# PY32Mxxx_DFP register map
Vendor: Puya; Series: PY32M; File version: 1.0.0
CPU: CM0+ r0p1, little endian, no MPU, no FPU, 4 interrupt priority bits
Registers are 32-bit, read-write, reset 0x0 unless marked. A register's access mark holds for its fields unless they carry their own. Offsets are from the block's base; [hi:lo] are bit positions; {n}, {i} and the like mark numbered series.

## CAN
Base 0x40006400
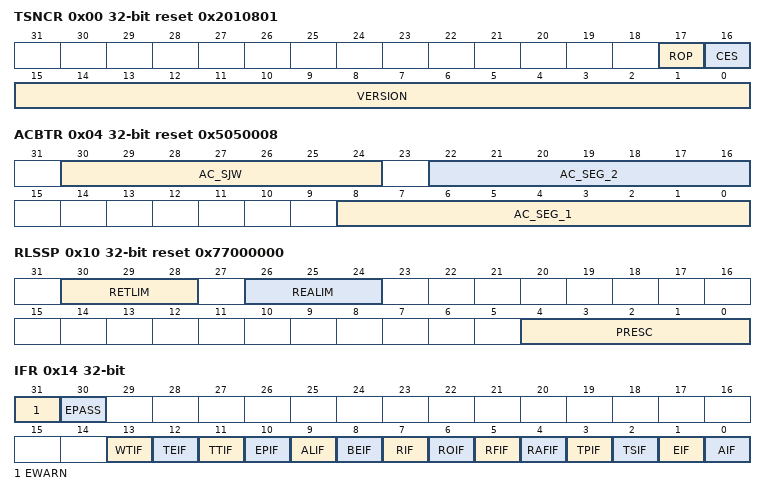
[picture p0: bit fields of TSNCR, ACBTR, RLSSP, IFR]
0x00 TSNCR reset 0x2010801
  [17] ROP, [16] CES, [15:0] VERSION ro
0x04 ACBTR reset 0x5050008
  [30:24] AC_SJW, [22:16] AC_SEG_2, [8:0] AC_SEG_1
0x10 RLSSP reset 0x77000000
  [30:28] RETLIM, [26:24] REALIM, [4:0] PRESC
0x14 IFR
  [31] EWARN ro, [30] EPASS ro, [13] WTIF, [12] TEIF, [11] TTIF, [10] EPIF, [9] ALIF, [8] BEIF, [7] RIF, [6] ROIF, [5] RFIF, [4] RAFIF, [3] TPIF, [2] TSIF, [1] EIF, [0] AIF
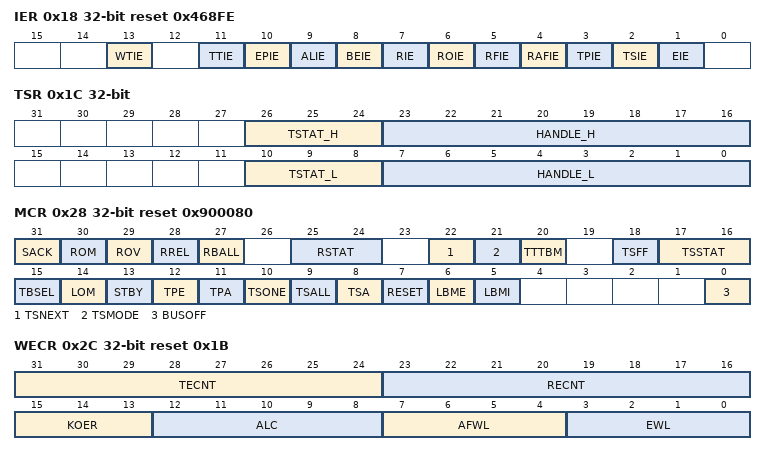
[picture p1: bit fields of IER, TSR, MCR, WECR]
0x18 IER reset 0x468FE
  [13] WTIE, [11] TTIE, [10] EPIE, [9] ALIE, [8] BEIE, [7] RIE, [6] ROIE, [5] RFIE, [4] RAFIE, [3] TPIE, [2] TSIE, [1] EIE
0x1C TSR ro
  [26:24] TSTAT_H, [23:16] HANDLE_H, [10:8] TSTAT_L, [7:0] HANDLE_L
0x28 MCR reset 0x900080
  [31] SACK, [30] ROM, [29] ROV ro, [28] RREL, [27] RBALL, [25:24] RSTAT ro, [22] TSNEXT, [21] TSMODE, [20] TTTBM, [18] TSFF ro, [17:16] TSSTAT ro, [15] TBSEL, [14] LOM, [13] STBY, [12] TPE, [11] TPA, [10] TSONE, [9] TSALL, [8] TSA, [7] RESET, [6] LBME, [5] LBMI, [0] BUSOFF
0x2C WECR reset 0x1B
  [31:24] TECNT ro, [23:16] RECNT ro, [15:13] KOER ro, [12:8] ALC ro, [7:4] AFWL, [3:0] EWL
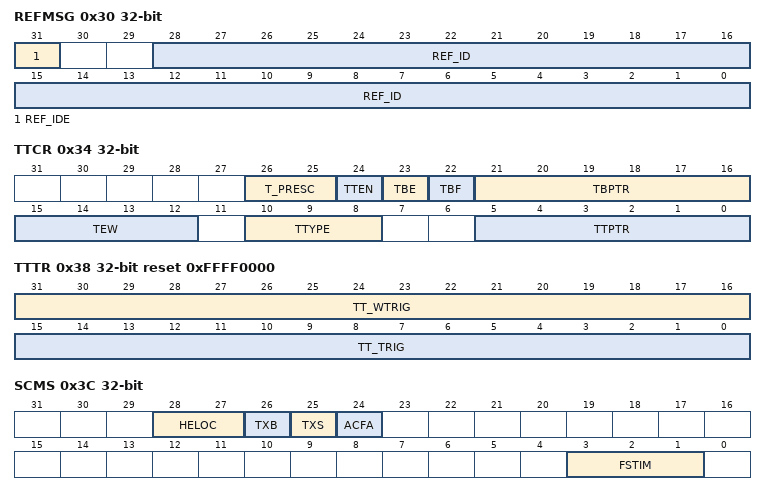
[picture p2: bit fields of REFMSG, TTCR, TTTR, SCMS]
0x30 REFMSG
  [31] REF_IDE, [28:0] REF_ID
0x34 TTCR
  [26:25] T_PRESC, [24] TTEN, [23] TBE, [22] TBF, [21:16] TBPTR, [15:12] TEW, [10:8] TTYPE, [5:0] TTPTR
0x38 TTTR reset 0xFFFF0000
  [31:16] TT_WTRIG, [15:0] TT_TRIG
0x3C SCMS
  [28:27] HELOC ro, [26] TXB ro, [25] TXS ro, [24] ACFA, [3:1] FSTIM
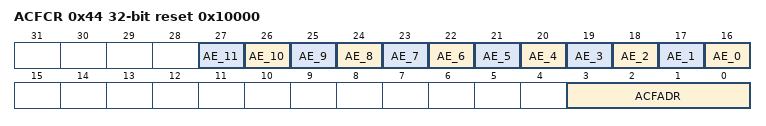
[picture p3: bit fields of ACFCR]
0x44 ACFCR reset 0x10000
  [n+16] AE_{n} (n=0..11), [3:0] ACFADR

## COMP1 — Comparator 1
Base 0x40010200
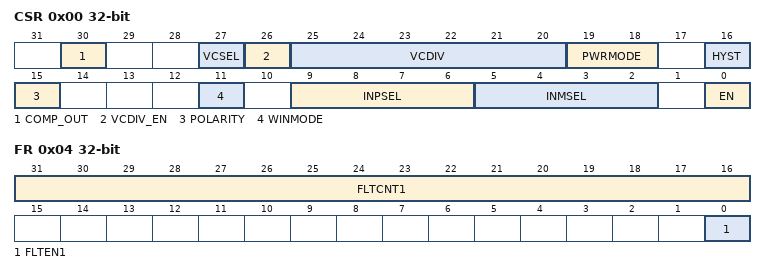
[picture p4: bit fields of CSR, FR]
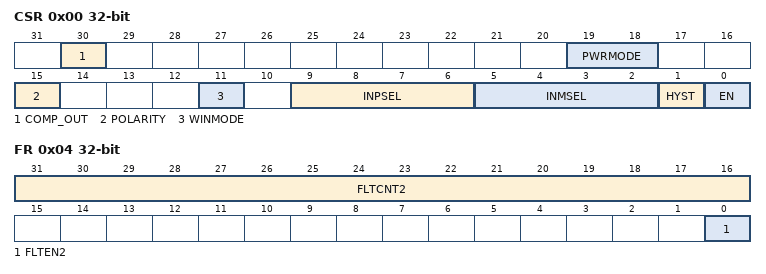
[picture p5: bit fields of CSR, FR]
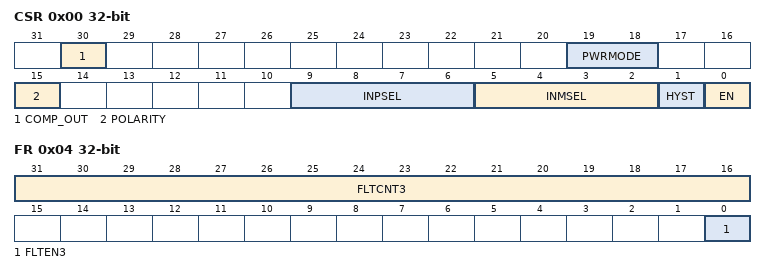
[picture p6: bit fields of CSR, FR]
0x00 CSR — COMP control and status register
  [30] COMP_OUT — Comparator output status
  [27] VCSEL
  [26] VCDIV_EN
  [25:20] VCDIV
  [19:18] PWRMODE — Comparator power mode selector
  [16] HYST — Comparator hysteresis enable selector
  [15] POLARITY — Comparator polarity selector
  [11] WINMODE — Comparator non-inverting input selector for window mode
  [9:6] INPSEL — Comparator signal selector for non-inverting input
  [5:2] INMSEL — Comparator signal selector for inverting input INM
  [0] EN — COMP enable bit
0x04 FR — Comparator Filter register
  [31:16] FLTCNT1 — Comparator filter and counter
  [0] FLTEN1 — Filter enable bit

## COMP2 — Comparator2
Base 0x40010210
0x00 CSR — COMP control and status register
  [30] COMP_OUT — Comparator output status
  [19:18] PWRMODE — Comparator power mode selector
  [15] POLARITY — Comparator polarity selector
  [11] WINMODE — Comparator non-inverting input selector for window mode
  [9:6] INPSEL — Comparator signal selector for non-inverting input
  [5:2] INMSEL — Comparator signal selector for inverting input INM
  [1] HYST — Comparator hysteresis enable selector
  [0] EN — COMP enable bit
0x04 FR — Comparator Filter register
  [31:16] FLTCNT2 — Comparator filter and counter
  [0] FLTEN2 — Filter enable bit

## COMP3 — Comparator3
Base 0x40010220
0x00 CSR — COMP control and status register
  [30] COMP_OUT — Comparator output status
  [19:18] PWRMODE — Comparator power mode selector
  [15] POLARITY — Comparator polarity selector
  [9:6] INPSEL — Comparator signal selector for non-inverting input
  [5:2] INMSEL — Comparator signal selector for inverting input INM
  [1] HYST — Comparator hysteresis enable selector
  [0] EN — COMP enable bit
0x04 FR — Comparator Filter register
  [31:16] FLTCNT3 — Comparator filter and counter
  [0] FLTEN3 — Filter enable bit

## CRC — CRC calculation unit
Base 0x40023000
0x00 DR reset 0xFFFFFFFF — Data register
  [31:0] DR — Data Register
0x04 IDR — Independent Data register
  [7:0] IDR
0x08 CR wo — Control register
  [0] RESET — Reset bit

## CTC
Base 0x40006C00
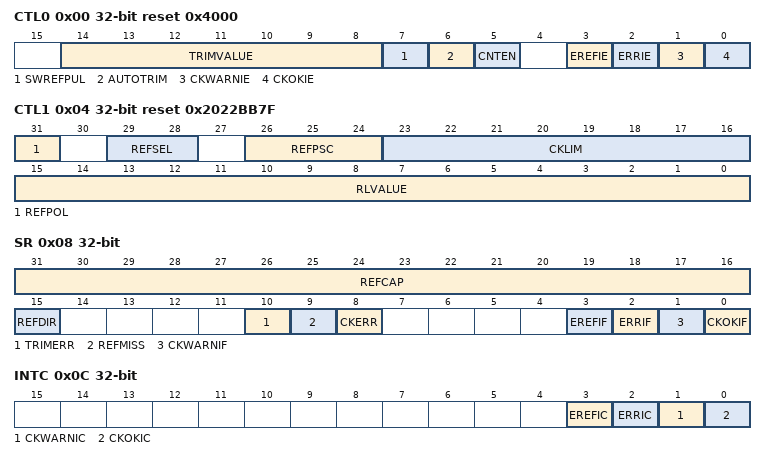
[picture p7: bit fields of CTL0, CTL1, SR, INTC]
0x00 CTL0 reset 0x4000
  [14:8] TRIMVALUE, [7] SWREFPUL wo, [6] AUTOTRIM, [5] CNTEN, [3] EREFIE, [2] ERRIE, [1] CKWARNIE, [0] CKOKIE
0x04 CTL1 reset 0x2022BB7F
  [31] REFPOL, [29:28] REFSEL, [26:24] REFPSC, [23:16] CKLIM, [15:0] RLVALUE
0x08 SR ro
  [31:16] REFCAP, [15] REFDIR, [10] TRIMERR, [9] REFMISS, [8] CKERR, [3] EREFIF, [2] ERRIF, [1] CKWARNIF, [0] CKOKIF
0x0C INTC wo
  [3] EREFIC, [2] ERRIC, [1] CKWARNIC, [0] CKOKIC
